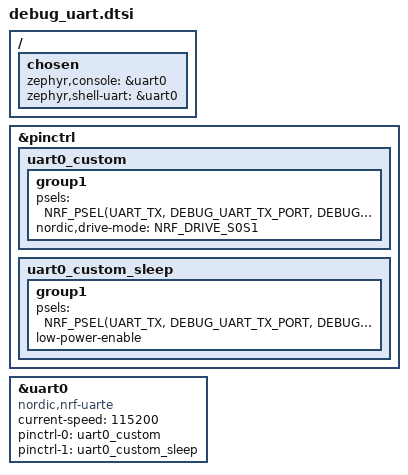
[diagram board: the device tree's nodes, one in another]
/*
overlayファイルの先頭で、これを書く。
ポートとピンは状況によっていじること。
#define DEBUG_UART_TX_PORT 1
#define DEBUG_UART_TX_PIN  12
#include <debug_uart.dtsi>
*/
/ {
    chosen {
        zephyr,console = &uart0;
        zephyr,shell-uart = &uart0;
    };
};

&pinctrl {
    uart0_custom: uart0_custom {
        group1 {
            psels = <NRF_PSEL(UART_TX, DEBUG_UART_TX_PORT, DEBUG_UART_TX_PIN)>;
            nordic,drive-mode = <NRF_DRIVE_S0S1>;
        };
    };

    uart0_custom_sleep: uart0_custom_sleep {
        group1 {
            psels = <NRF_PSEL(UART_TX, DEBUG_UART_TX_PORT, DEBUG_UART_TX_PIN)>;
            low-power-enable;
        };
    };
};

&uart0 {
    compatible = "nordic,nrf-uarte";
    status = "okay";
    current-speed = <115200>;
    pinctrl-0 = <&uart0_custom>;
    pinctrl-1 = <&uart0_custom_sleep>;
    pinctrl-names = "default", "sleep";
};
